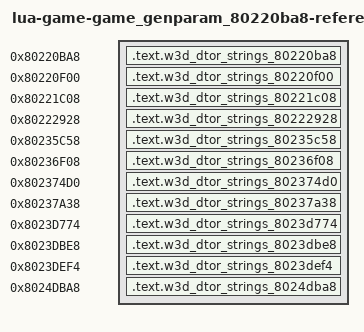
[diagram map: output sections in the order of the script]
/* Generated reference-only placements. All bodies are source-built. */
OUTPUT_FORMAT("elf32-powerpc")
OUTPUT_ARCH(powerpc)
ENTRY(w3d_dtor_strings_80220ba8)
_SDA_BASE_ = 0x804b2540;
_SDA2_BASE_ = 0x804c2540;
fn_801b4c6c = 0x801b4c6c;
fn_801ea138 = 0x801ea138;
fn_801ea740 = 0x801ea740;
fn_8020c5c4 = 0x8020c5c4;
fn_8021f234 = 0x8021f234;
fn_8023b5f0 = 0x8023b5f0;
fn_8023d398 = 0x8023d398;
fn_8023d5b0 = 0x8023d5b0;
fn_80341588 = 0x80341588;
w3d_vtable_8041a460 = 0x8041a460;
w3d_vtable_8041a4d8 = 0x8041a4d8;
w3d_vtable_8041a528 = 0x8041a528;
w3d_vtable_8041a550 = 0x8041a550;
w3d_vtable_8041a720 = 0x8041a720;
w3d_vtable_8041a770 = 0x8041a770;
w3d_vtable_8041a7c0 = 0x8041a7c0;
w3d_vtable_8041a8d8 = 0x8041a8d8;
w3d_vtable_8041ab58 = 0x8041ab58;
w3d_vtable_8041ab80 = 0x8041ab80;
w3d_vtable_8041abd0 = 0x8041abd0;
w3d_vtable_8041b7f8 = 0x8041b7f8;
SECTIONS {
  .text.w3d_dtor_strings_80220ba8 0x80220ba8 : { *(.text.w3d_dtor_strings_80220ba8) }
  .text.w3d_dtor_strings_80220f00 0x80220f00 : { *(.text.w3d_dtor_strings_80220f00) }
  .text.w3d_dtor_strings_80221c08 0x80221c08 : { *(.text.w3d_dtor_strings_80221c08) }
  .text.w3d_dtor_strings_80222928 0x80222928 : { *(.text.w3d_dtor_strings_80222928) }
  .text.w3d_dtor_strings_80235c58 0x80235c58 : { *(.text.w3d_dtor_strings_80235c58) }
  .text.w3d_dtor_strings_80236f08 0x80236f08 : { *(.text.w3d_dtor_strings_80236f08) }
  .text.w3d_dtor_strings_802374d0 0x802374d0 : { *(.text.w3d_dtor_strings_802374d0) }
  .text.w3d_dtor_strings_80237a38 0x80237a38 : { *(.text.w3d_dtor_strings_80237a38) }
  .text.w3d_dtor_strings_8023d774 0x8023d774 : { *(.text.w3d_dtor_strings_8023d774) }
  .text.w3d_dtor_strings_8023dbe8 0x8023dbe8 : { *(.text.w3d_dtor_strings_8023dbe8) }
  .text.w3d_dtor_strings_8023def4 0x8023def4 : { *(.text.w3d_dtor_strings_8023def4) }
  .text.w3d_dtor_strings_8024dba8 0x8024dba8 : { *(.text.w3d_dtor_strings_8024dba8) }
  /DISCARD/ : { *(.text*) *(.rodata*) *(.data*) *(.bss*) *(.sdata*) *(.sbss*) *(.comment) }
}
